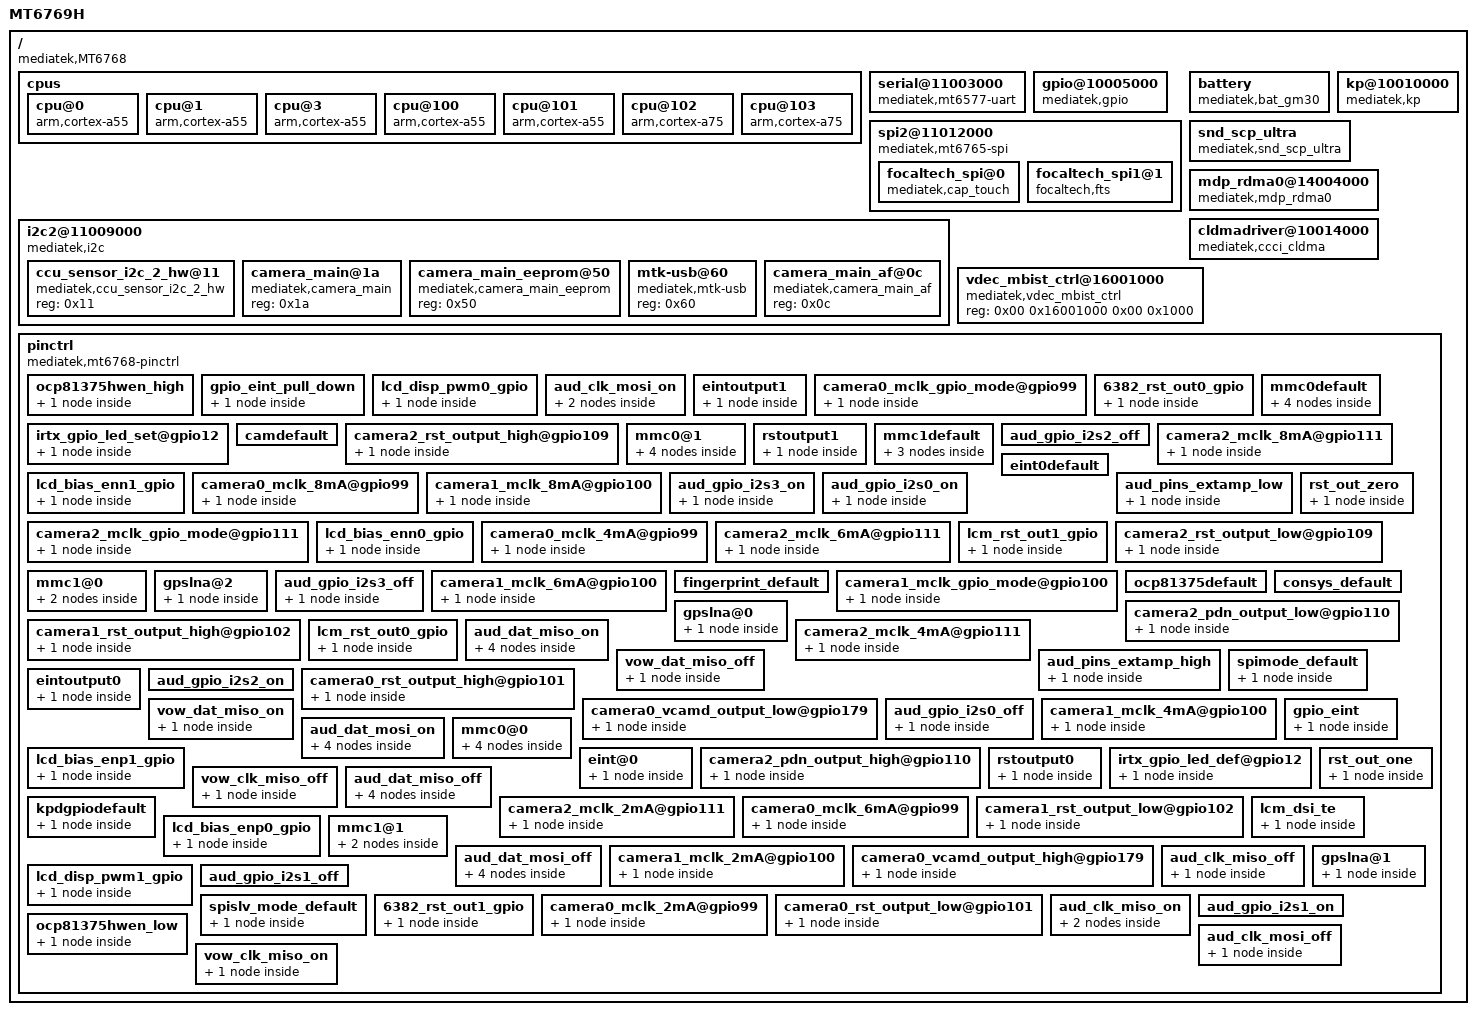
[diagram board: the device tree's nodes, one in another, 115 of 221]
/dts-v1/;

/ {
    model-part-name = "MT6769H";
	#address-cells = <0x02>;
	model = "MT6769H";
	#size-cells = <0x02>;
	interrupt-parent = <0x01>;
	compatible = "mediatek,MT6768";
	model-external-name = "MT6769H";

    cpus {
        #address-cells = <0x01>;
		#size-cells = <0x00>;
        cpu@0 {
            capacity-dmips-mhz = <0x1ef>;
			clock-frequency = <0x65633340>;
			cpu-idle-states = <0x03 0x04 0x05 0x06 0x07 0x08 0x09>;
			device_type = "cpu";
			compatible = "arm,cortex-a55";
			dynamic-power-coefficient = <0x55>;
			reg = <0x00>;
			enable-method = "psci";
			phandle = <0x0b>;
			operating-points-v2 = <0x02>;
        };
        cpu@1 {
            capacity-dmips-mhz = <0x1ef>;
			clock-frequency = <0x65633340>;
			cpu-idle-states = <0x03 0x04 0x05 0x06 0x07 0x08 0x09>;
			device_type = "cpu";
			compatible = "arm,cortex-a55";
			dynamic-power-coefficient = <0x55>;
			reg = <0x100>;
			enable-method = "psci";
			phandle = <0x0c>;
			operating-points-v2 = <0x02>;
        };
        cpu@3 {
			capacity-dmips-mhz = <0x1ef>;
			clock-frequency = <0x65633340>;
			cpu-idle-states = <0x03 0x04 0x05 0x06 0x07 0x08 0x09>;
			device_type = "cpu";
			compatible = "arm,cortex-a55";
			dynamic-power-coefficient = <0x55>;
			reg = <0x300>;
			enable-method = "psci";
			phandle = <0x0e>;
			operating-points-v2 = <0x02>;
		};
        cpu@100 {
			capacity-dmips-mhz = <0x1ef>;
			clock-frequency = <0x65633340>;
			cpu-idle-states = <0x03 0x04 0x05 0x06 0x07 0x08 0x09>;
			device_type = "cpu";
			compatible = "arm,cortex-a55";
			dynamic-power-coefficient = <0x55>;
			reg = <0x400>;
			enable-method = "psci";
			phandle = <0x0f>;
			operating-points-v2 = <0x02>;
		};
        cpu@101 {
			capacity-dmips-mhz = <0x1ef>;
			clock-frequency = <0x65633340>;
			cpu-idle-states = <0x03 0x04 0x05 0x06 0x07 0x08 0x09>;
			device_type = "cpu";
			compatible = "arm,cortex-a55";
			dynamic-power-coefficient = <0x55>;
			reg = <0x500>;
			enable-method = "psci";
			phandle = <0x10>;
			operating-points-v2 = <0x02>;
		};
        cpu@102 {
			capacity-dmips-mhz = <0x400>;
			clock-frequency = <0x8166d4c0>;
			cpu-idle-states = <0x03 0x04 0x05 0x06 0x07 0x08 0x09>;
			device_type = "cpu";
			compatible = "arm,cortex-a75";
			dynamic-power-coefficient = <0x113>;
			reg = <0x600>;
			enable-method = "psci";
			phandle = <0x11>;
			operating-points-v2 = <0x0a>;
		};
        cpu@103 {
			capacity-dmips-mhz = <0x400>;
			clock-frequency = <0x8166d4c0>;
			cpu-idle-states = <0x03 0x04 0x05 0x06 0x07 0x08 0x09>;
			device_type = "cpu";
			compatible = "arm,cortex-a75";
			dynamic-power-coefficient = <0x113>;
			reg = <0x700>;
			enable-method = "psci";
			phandle = <0x12>;
			operating-points-v2 = <0x0a>;
		};
    };

    serial@11003000 {
		clock-names = "baud\0bus";
		interrupts = <0x00 0x71 0x08>;
		clocks = <0x15 0x26 0x17>;
		dma-names = "tx\0rx";
		compatible = "mediatek,mt6577-uart";
		reg = <0x00 0x11003000 0x00 0x1000>;
		phandle = <0xc0>;
		dmas = <0x39 0x02 0x39 0x03>;
	};

    gpio@10005000 {
		gpio_init_default = <0x00 0x00 0x00 0x00 0x01 0x01 0x01 0x01 0x00 0x00 0x00 0x00 0x01 0x01 0x02 0x00 0x00 0x00 0x01 0x00 0x01 0x03 0x00 0x00 0x00 0x01 0x01 0x00 0x04 0x00 0x00 0x00 0x01 0x01 0x01 0x05 0x00 0x00 0x00 0x01 0x00 0x00 0x06 0x00 0x00 0x00 0x01 0x01 0x01 0x07 0x00 0x00 0x00 0x01 0x01 0x00 0x08 0x00 0x00 0x00 0x01 0x01 0x00 0x09 0x00 0x00 0x00 0x01 0x00 0x00 0x0a 0x00 0x00 0x00 0x01 0x01 0x00 0x0b 0x01 0x00 0x00 0x01 0x00 0x00 0x0c 0x02 0x00 0x00 0x01 0x00 0x00 0x0d 0x02 0x00 0x00 0x01 0x00 0x00 0x0e 0x02 0x01 0x00 0x00 0x00 0x00 0x0f 0x02 0x01 0x00 0x00 0x00 0x00 0x10 0x02 0x01 0x00 0x00 0x00 0x00 0x11 0x00 0x00 0x00 0x01 0x00 0x01 0x12 0x00 0x00 0x00 0x01 0x01 0x01 0x13 0x00 0x01 0x00 0x01 0x00 0x01 0x14 0x00 0x01 0x00 0x01 0x00 0x01 0x15 0x00 0x00 0x00 0x01 0x01 0x00 0x16 0x00 0x00 0x00 0x01 0x00 0x00 0x17 0x00 0x00 0x00 0x00 0x00 0x00 0x18 0x05 0x00 0x00 0x01 0x00 0x00 0x19 0x02 0x00 0x00 0x01 0x00 0x00 0x1a 0x02 0x00 0x00 0x00 0x00 0x00 0x1b 0x02 0x01 0x00 0x00 0x00 0x00 0x1c 0x02 0x00 0x00 0x00 0x00 0x00 0x1d 0x00 0x01 0x00 0x00 0x00 0x00 0x1e 0x00 0x01 0x00 0x00 0x00 0x00 0x1f 0x00 0x01 0x00 0x01 0x01 0x00 0x20 0x01 0x00 0x00 0x01 0x00 0x00 0x21 0x01 0x01 0x00 0x00 0x00 0x00 0x22 0x01 0x01 0x00 0x00 0x00 0x00 0x23 0x01 0x01 0x00 0x00 0x00 0x00 0x24 0x00 0x01 0x01 0x00 0x00 0x00 0x25 0x02 0x01 0x00 0x00 0x00 0x00 0x26 0x00 0x00 0x00 0x00 0x00 0x01 0x27 0x00 0x00 0x00 0x01 0x01 0x01 0x28 0x02 0x00 0x00 0x01 0x00 0x00 0x29 0x00 0x00 0x00 0x01 0x01 0x01 0x2a 0x00 0x01 0x00 0x01 0x01 0x01 0x2b 0x01 0x01 0x00 0x00 0x00 0x00 0x2c 0x01 0x00 0x00 0x01 0x00 0x00 0x2d 0x00 0x01 0x00 0x00 0x00 0x00 0x2e 0x01 0x00 0x00 0x01 0x01 0x00 0x2f 0x01 0x00 0x00 0x01 0x01 0x00 0x30 0x01 0x00 0x00 0x01 0x01 0x01 0x31 0x01 0x00 0x00 0x01 0x01 0x01 0x32 0x01 0x00 0x00 0x01 0x01 0x01 0x33 0x01 0x00 0x00 0x01 0x01 0x01 0x34 0x01 0x00 0x00 0x01 0x00 0x00 0x35 0x01 0x00 0x00 0x01 0x00 0x00 0x36 0x01 0x00 0x00 0x01 0x00 0x00 0x37 0x01 0x00 0x00 0x01 0x00 0x00 0x38 0x01 0x00 0x00 0x01 0x00 0x00 0x39 0x01 0x00 0x00 0x01 0x00 0x00 0x3a 0x00 0x00 0x00 0x01 0x00 0x00 0x3b 0x01 0x00 0x00 0x01 0x00 0x00 0x3c 0x01 0x00 0x00 0x01 0x00 0x00 0x3d 0x01 0x00 0x00 0x01 0x00 0x00 0x3e 0x01 0x00 0x00 0x01 0x00 0x00 0x3f 0x01 0x00 0x00 0x01 0x00 0x00 0x40 0x01 0x00 0x00 0x01 0x00 0x00 0x41 0x01 0x00 0x00 0x01 0x00 0x00 0x42 0x01 0x00 0x00 0x01 0x00 0x00 0x43 0x01 0x00 0x00 0x01 0x00 0x00 0x44 0x01 0x00 0x00 0x01 0x00 0x00 0x45 0x01 0x00 0x00 0x01 0x00 0x00 0x46 0x01 0x00 0x00 0x01 0x00 0x00 0x47 0x01 0x00 0x00 0x01 0x00 0x00 0x48 0x01 0x00 0x00 0x01 0x00 0x00 0x49 0x01 0x00 0x00 0x01 0x00 0x00 0x4a 0x01 0x00 0x00 0x01 0x00 0x00 0x4b 0x01 0x00 0x00 0x01 0x00 0x00 0x4c 0x01 0x00 0x00 0x01 0x00 0x00 0x4d 0x01 0x00 0x00 0x01 0x00 0x00 0x4e 0x01 0x00 0x00 0x01 0x00 0x00 0x4f 0x00 0x00 0x00 0x01 0x00 0x00 0x50 0x00 0x00 0x00 0x01 0x00 0x00 0x51 0x02 0x00 0x00 0x01 0x01 0x01 0x52 0x01 0x00 0x00 0x01 0x01 0x01 0x53 0x01 0x00 0x00 0x01 0x01 0x01 0x54 0x02 0x00 0x00 0x01 0x01 0x01 0x55 0x02 0x00 0x00 0x01 0x00 0x00 0x56 0x02 0x01 0x00 0x00 0x00 0x00 0x57 0x02 0x01 0x00 0x00 0x00 0x00 0x58 0x02 0x01 0x00 0x00 0x00 0x00 0x59 0x01 0x00 0x00 0x01 0x01 0x01 0x5a 0x01 0x00 0x00 0x01 0x01 0x01 0x5b 0x00 0x00 0x00 0x00 0x00 0x00 0x5c 0x01 0x01 0x00 0x00 0x00 0x00 0x5d 0x01 0x00 0x00 0x01 0x01 0x00 0x5e 0x00 0x01 0x00 0x00 0x00 0x00 0x5f 0x01 0x00 0x00 0x01 0x01 0x00 0x60 0x01 0x01 0x00 0x00 0x00 0x00 0x61 0x00 0x00 0x00 0x01 0x01 0x00 0x62 0x00 0x00 0x00 0x01 0x00 0x00 0x63 0x01 0x01 0x00 0x00 0x00 0x00 0x64 0x01 0x01 0x00 0x00 0x00 0x00 0x65 0x00 0x01 0x00 0x00 0x00 0x00 0x66 0x00 0x01 0x00 0x00 0x00 0x00 0x67 0x01 0x00 0x00 0x01 0x01 0x01 0x68 0x01 0x00 0x00 0x01 0x01 0x01 0x69 0x01 0x00 0x00 0x01 0x01 0x01 0x6a 0x01 0x00 0x00 0x01 0x01 0x01 0x6b 0x00 0x00 0x00 0x00 0x01 0x00 0x6c 0x00 0x00 0x00 0x00 0x00 0x00 0x6d 0x00 0x01 0x00 0x00 0x00 0x00 0x6e 0x00 0x01 0x00 0x00 0x00 0x00 0x6f 0x01 0x01 0x00 0x00 0x00 0x00 0x70 0x00 0x00 0x00 0x00 0x00 0x00 0x71 0x00 0x00 0x00 0x01 0x00 0x00 0x72 0x00 0x00 0x00 0x01 0x00 0x00 0x73 0x00 0x00 0x00 0x01 0x00 0x00 0x74 0x00 0x00 0x00 0x01 0x00 0x00 0x75 0x00 0x00 0x00 0x01 0x00 0x00 0x76 0x00 0x00 0x00 0x01 0x00 0x00 0x77 0x00 0x00 0x00 0x01 0x00 0x00 0x78 0x00 0x00 0x00 0x01 0x00 0x00 0x79 0x00 0x00 0x00 0x01 0x00 0x00 0x86 0x01 0x00 0x00 0x01 0x00 0x01 0x87 0x01 0x01 0x00 0x00 0x00 0x00 0x88 0x01 0x01 0x00 0x00 0x00 0x00 0x89 0x01 0x01 0x00 0x00 0x00 0x00 0x8a 0x01 0x01 0x00 0x00 0x00 0x00 0x8b 0x01 0x01 0x00 0x00 0x00 0x00 0x8c 0x01 0x00 0x00 0x01 0x00 0x00 0x8d 0x01 0x00 0x00 0x01 0x00 0x00 0x8e 0x01 0x00 0x00 0x01 0x00 0x00 0x8f 0x01 0x00 0x00 0x01 0x00 0x00 0x90 0x01 0x00 0x00 0x01 0x00 0x00 0x91 0x01 0x01 0x00 0x00 0x00 0x00 0x92 0x01 0x01 0x00 0x00 0x00 0x00 0x93 0x01 0x01 0x00 0x00 0x00 0x00 0x94 0x01 0x01 0x00 0x00 0x00 0x00 0x95 0x01 0x01 0x00 0x00 0x00 0x00 0x96 0x00 0x01 0x00 0x00 0x00 0x00 0x97 0x04 0x01 0x00 0x00 0x00 0x00 0x98 0x00 0x01 0x00 0x00 0x00 0x00 0x99 0x00 0x01 0x00 0x00 0x00 0x00 0x9a 0x01 0x01 0x00 0x00 0x00 0x00 0x9b 0x01 0x00 0x00 0x01 0x01 0x00 0x9c 0x01 0x01 0x00 0x00 0x00 0x00 0x9d 0x01 0x01 0x00 0x00 0x00 0x00 0x9e 0x00 0x01 0x00 0x00 0x00 0x00 0x9f 0x00 0x01 0x00 0x00 0x00 0x00 0xa0 0x00 0x01 0x00 0x01 0x01 0x00 0xa1 0x01 0x00 0x00 0x01 0x01 0x01 0xa2 0x01 0x00 0x00 0x01 0x01 0x01 0xa3 0x01 0x00 0x00 0x01 0x01 0x01 0xa4 0x01 0x00 0x00 0x01 0x01 0x01 0xa5 0x00 0x01 0x00 0x00 0x00 0x00 0xa6 0x00 0x01 0x00 0x00 0x00 0x00 0xa7 0x01 0x00 0x00 0x01 0x00 0x00 0xa8 0x01 0x00 0x00 0x01 0x00 0x00 0xa9 0x00 0x01 0x00 0x00 0x00 0x00 0xaa 0x01 0x00 0x00 0x01 0x01 0x01 0xab 0x01 0x01 0x00 0x00 0x00 0x01 0xac 0x01 0x01 0x00 0x00 0x00 0x00 0xad 0x01 0x01 0x00 0x00 0x00 0x00 0xae 0x01 0x00 0x00 0x01 0x01 0x00 0xaf 0x01 0x00 0x00 0x01 0x01 0x01 0xb0 0x01 0x00 0x00 0x01 0x01 0x01 0xb2 0x00 0x01 0x00 0x00 0x00 0x00 0xb3 0x00 0x01 0x00 0x00 0x00 0x00 0xb4 0x00 0x00 0x00 0x01 0x00 0x00 0xb5 0x00 0x00 0x00 0x01 0x00 0x00 0xb6 0x00 0x00 0x00 0x01 0x00 0x00 0xb7 0x00 0x00 0x00 0x01 0x00 0x00 0xb8 0x00 0x00 0x00 0x01 0x00 0x00 0xb9 0x00 0x00 0x00 0x01 0x00 0x00 0xba 0x00 0x00 0x00 0x01 0x00 0x00>;
		compatible = "mediatek,gpio\0syscon";
		reg = <0x00 0x10005000 0x00 0x1000>;
		phandle = <0x16>;
	};

    spi2@11012000 {
		#address-cells = <0x01>;
		clock-names = "parent-clk\0sel-clk\0spi-clk";
		interrupts = <0x00 0x91 0x08>;
		clocks = <0x14 0x0b 0x14 0x5b 0x26 0x37>;
		#size-cells = <0x00>;
		compatible = "mediatek,mt6765-spi";
		status = "okay";
		reg = <0x00 0x11012000 0x00 0x1000>;
		phandle = <0xd6>;
		mediatek,pad-select = <0x00>;

		focaltech_spi@0 {
			spi-max-frequency = <0x5b8d80>;
			compatible = "mediatek,cap_touch";
			reg = <0x00>;
		};

		focaltech_spi1@1 {
			spi-max-frequency = <0x5b8d80>;
			compatible = "focaltech,fts";
			reg = <0x00>;
		};
	};

    battery {
		g_FG_PSEUDO100_T0 = <0x5f>;
		SHUTDOWN_1_TIME = <0x78>;
		battery1_profile_t3_col = <0x03>;
		battery0_profile_t0 = <0x00 0xaba4 0x3f2 0x203 0xaaf3 0x3f2 0x405 0xaa6c 0x3f1 0x608 0xa9ee 0x3ea 0x80b 0xa970 0x3f0 0xa0e 0xa8ef 0x3eb 0xc10 0xa86a 0x3f2 0xe13 0xa7ec 0x3ee 0x1016 0xa76e 0x3e8 0x1219 0xa6ef 0x3ed 0x141b 0xa671 0x3f2 0x161e 0xa5f3 0x3f2 0x1821 0xa575 0x3f2 0x1a24 0xa4f7 0x3f2 0x1c26 0xa480 0x3f9 0x1e29 0xa405 0x3fc 0x202c 0xa38f 0x3fc 0x222f 0xa313 0x3f3 0x2431 0xa29e 0x3fb 0x2634 0xa22a 0x3fc 0x2837 0xa1ad 0x3fc 0x2a3a 0xa13a 0x3fd 0x2c3c 0xa0d0 0x406 0x2e3f 0xa05c 0x406 0x3042 0x9fe9 0x408 0x3245 0x9f78 0x410 0x3447 0x9f0f 0x413 0x364a 0x9ea2 0x41e 0x384d 0x9e37 0x424 0x3a50 0x9dd4 0x429 0x3c52 0x9d6a 0x42e 0x3e55 0x9d01 0x42e 0x4058 0x9c9f 0x43a 0x425b 0x9c40 0x442 0x445d 0x9bda 0x442 0x4660 0x9b81 0x44a 0x4863 0x9b24 0x465 0x4a66 0x9acf 0x461 0x4c68 0x9a71 0x469 0x4e6b 0x9a1c 0x487 0x506e 0x99c8 0x489 0x5271 0x9969 0x4a5 0x5473 0x98fd 0x491 0x5676 0x987e 0x47c 0x5879 0x97f7 0x439 0x5a7c 0x977f 0x415 0x5c7e 0x971c 0x403 0x5e81 0x96cc 0x3f8 0x6084 0x9687 0x3f2 0x6287 0x9643 0x3ed 0x6489 0x95fe 0x3e8 0x668c 0x95c5 0x3e8 0x688f 0x9591 0x3ee 0x6a92 0x955c 0x3f2 0x6c94 0x9528 0x3f2 0x6e97 0x94fb 0x3ea 0x709a 0x94d1 0x3f9 0x729d 0x949e 0x3f3 0x749f 0x9473 0x3fb 0x76a2 0x9453 0x406 0x78a5 0x9429 0x406 0x7aa8 0x940a 0x40f 0x7caa 0x93e9 0x407 0x7ead 0x93c1 0x410 0x80b0 0x93a4 0x412 0x82b3 0x938f 0x41d 0x84b5 0x9377 0x424 0x86b8 0x935b 0x424 0x88bb 0x9346 0x428 0x8abe 0x932c 0x429 0x8cc0 0x930d 0x424 0x8ec3 0x92dc 0x40d 0x90c6 0x92a3 0x3f0 0x92c9 0x926f 0x3ef 0x94cb 0x9248 0x3f2 0x96ce 0x9221 0x3fa 0x98d1 0x91ff 0x3fc 0x9ad4 0x91e0 0x3fc 0x9cd6 0x91b7 0x3fc 0x9ed9 0x9197 0x3fc 0xa0dc 0x9177 0x406 0xa2df 0x9157 0x411 0xa4e1 0x912b 0x419 0xa6e4 0x90ec 0x410 0xa8e7 0x90ad 0x40e 0xaaea 0x9070 0x40b 0xacec 0x9035 0x41d 0xaeef 0x8fe4 0x415 0xb0f2 0x8f9b 0x404 0xb2f5 0x8f7b 0x423 0xb4f7 0x8f60 0x448 0xb6fa 0x8f35 0x462 0xb8fd 0x8ed5 0x477 0xbb00 0x8e13 0x477 0xbd02 0x8cd5 0x47b 0xbf05 0x8b03 0x46e 0xc108 0x88a7 0x472 0xc30b 0x85d9 0x47d 0xc50d 0x825c 0x4a3 0xc710 0x821e 0x4a6>;
		TEMPERATURE_T4 = <0xfffffff6>;
		CAR_TUNE_VALUE = <0x64>;
		battery0_profile_t1_num = <0x64>;
		battery0_profile_t5_num = <0x64>;
		TEMPERATURE_T2 = <0x0a>;
		battery1_profile_t2_num = <0x64>;
		battery0_profile_t3_col = <0x03>;
		TEMPERATURE_T0 = <0x32>;
		DIFFERENCE_FULLOCV_ITH = <0xc8>;
		battery1_profile_t0_col = <0x03>;
		battery1_profile_t4 = <0x00 0xab8a 0x1c20 0x1f4 0xaa9e 0x1c20 0x3e8 0xa9e1 0x1be9 0x5dc 0xa930 0x1b85 0x7d0 0xa892 0x1b17 0x9c4 0xa7fa 0x1ab3 0xbb8 0xa769 0x1a59 0xdac 0xa6dd 0x19fa 0xfa0 0xa652 0x198f 0x1194 0xa5cc 0x193e 0x1388 0xa550 0x18f9 0x157c 0xa4ce 0x18a4 0x1770 0xa452 0x1860 0x1964 0xa3dc 0x1831 0x1b58 0xa363 0x17fa 0x1d4c 0xa2f1 0x17cd 0x1f40 0xa27b 0x1796 0x2134 0xa20b 0x177d 0x2328 0xa19c 0x1761 0x251c 0xa126 0x1740 0x2710 0xa0b6 0x1741 0x2904 0xa047 0x171b 0x2af8 0x9fdd 0x170a 0x2cec 0x9f7d 0x1711 0x2ee0 0x9f20 0x1719 0x30d4 0x9eb7 0x1702 0x32c8 0x9e41 0x16dd 0x34bc 0x9dbc 0x16a6 0x36b0 0x9d30 0x1660 0x38a4 0x9ca5 0x163a 0x3a98 0x9c22 0x1629 0x3c8c 0x9ba6 0x1621 0x3e80 0x9b3a 0x162b 0x4074 0x9ad7 0x1633 0x4268 0x9a7a 0x1649 0x445c 0x9a23 0x1651 0x4650 0x99cc 0x1630 0x4844 0x9972 0x1619 0x4a38 0x9918 0x1612 0x4c2c 0x98bb 0x15f2 0x4e20 0x985b 0x15cc 0x5014 0x97fb 0x159f 0x5208 0x979e 0x1586 0x53fc 0x9744 0x1568 0x55f0 0x96ea 0x1548 0x57e4 0x9696 0x1531 0x59d8 0x9649 0x1513 0x5bcc 0x95fb 0x14fa 0x5dc0 0x95b7 0x1511 0x5fb4 0x9573 0x150c 0x61a8 0x9535 0x150c 0x639c 0x94fa 0x151b 0x6590 0x94c9 0x153b 0x6784 0x9494 0x1543 0x6978 0x9468 0x155e 0x6b6c 0x943a 0x1570 0x6d60 0x9415 0x1590 0x6f54 0x93f0 0x15b5 0x7148 0x93d1 0x15ed 0x733c 0x93ae 0x1621 0x7530 0x9393 0x1642 0x7724 0x9377 0x1679 0x7918 0x935b 0x16a6 0x7b0c 0x933f 0x16d5 0x7d00 0x9320 0x1702 0x7ef4 0x9304 0x172a 0x80e8 0x92e5 0x1757 0x82dc 0x92c3 0x178e 0x84d0 0x92a4 0x17b6 0x86c4 0x9282 0x17db 0x88b8 0x925c 0x1801 0x8aac 0x9231 0x1822 0x8ca0 0x920c 0x1838 0x8e94 0x91e0 0x184f 0x9088 0x91b2 0x1877 0x927c 0x917a 0x189c 0x9470 0x9142 0x18c4 0x9664 0x9107 0x18e2 0x9858 0x90c3 0x1919 0x9a4c 0x9079 0x193a 0x9c40 0x902b 0x1967 0x9e34 0x8fd8 0x1987 0xa028 0x8f7e 0x199e 0xa21c 0x8f1e 0x19c6 0xa410 0x8eba 0x19f0 0xa604 0x8e51 0x1a20 0xa7f8 0x8dde 0x1a57 0xa9ec 0x8d6c 0x1aae 0xabe0 0x8cf3 0x1b03 0xadd4 0x8c7a 0x1b76 0xafc8 0x8c01 0x1c0a 0xb1bc 0x8b8e 0x1cb4 0xb3b0 0x8b1f 0x1dae 0xb5a4 0x8ab8 0x1ef8 0xb798 0x8a52 0x20d3 0xb98c 0x89e2 0x237b 0xbb80 0x895d 0x2783 0xbd74 0x889a 0x2d1e 0xbf68 0x8748 0x3451 0xc15c 0x8523 0x3e3f>;
		battery1_profile_t4_col = <0x03>;
		battery_id_gpio = <0x20 0x17 0x00>;
		battery0_profile_t5 = <0x00 0xab36 0x4ca4 0x203 0xa960 0x4cab 0x405 0xa7c0 0x4d2a 0x608 0xa650 0x4d05 0x80b 0xa529 0x4b03 0xa0e 0xa42b 0x48de 0xc10 0xa33f 0x4712 0xe13 0xa269 0x45ef 0x1016 0xa1ad 0x44e1 0x1219 0xa100 0x4406 0x141b 0xa049 0x4302 0x161e 0x9f86 0x41d7 0x1821 0x9ebf 0x40db 0x1a24 0x9dfd 0x3f7d 0x1c26 0x9d4a 0x3e5d 0x1e29 0x9cae 0x3da9 0x202c 0x9c22 0x3cad 0x222f 0x9b89 0x3ba2 0x2431 0x9b20 0x3b37 0x2634 0x9ab8 0x3b09 0x2837 0x9a4f 0x3ac2 0x2a3a 0x99dc 0x3a64 0x2c3c 0x997d 0x3a02 0x2e3f 0x9915 0x39fc 0x3042 0x98b7 0x39bb 0x3245 0x984c 0x3984 0x3447 0x97e0 0x3a2c 0x364a 0x978c 0x38bf 0x384d 0x9738 0x37f5 0x3a50 0x96e4 0x3856 0x3c52 0x9694 0x3874 0x3e55 0x964b 0x3877 0x4058 0x95fc 0x3895 0x425b 0x95bb 0x38f2 0x445d 0x9580 0x38ea 0x4660 0x9541 0x38c2 0x4863 0x9502 0x38f6 0x4a66 0x94c3 0x395f 0x4c68 0x9484 0x394c 0x4e6b 0x9456 0x3842 0x506e 0x9423 0x385a 0x5271 0x93ef 0x39f4 0x5473 0x93b1 0x3a3f 0x5676 0x937c 0x3a87 0x5879 0x933f 0x3abe 0x5a7c 0x9312 0x3b0a 0x5c7e 0x92d5 0x3b59 0x5e81 0x929e 0x3b93 0x6084 0x9262 0x3bc7 0x6287 0x922d 0x3c14 0x6489 0x91f9 0x3c68 0x668c 0x91c5 0x3cb2 0x688f 0x918c 0x3cf0 0x6a92 0x9152 0x3d45 0x6c94 0x911e 0x3d9c 0x6e97 0x90e9 0x3e00 0x709a 0x90b5 0x3e50 0x729d 0x9080 0x3eae 0x749f 0x904c 0x3f2f 0x76a2 0x9017 0x3f73 0x78a5 0x8fe3 0x4014 0x7aa8 0x8faf 0x4024 0x7caa 0x8f84 0x40ae 0x7ead 0x8f46 0x410f 0x80b0 0x8f1c 0x418e 0x82b3 0x8ee8 0x4219 0x84b5 0x8ebc 0x42af 0x86b8 0x8e88 0x432c 0x88bb 0x8e53 0x43c4 0x8abe 0x8e22 0x4457 0x8cc0 0x8df5 0x44f2 0x8ec3 0x8dc1 0x458a 0x90c6 0x8d8c 0x480c 0x92c9 0x8d58 0x486e 0x94cb 0x8d23 0x4746 0x96ce 0x8cfb 0x48a9 0x98d1 0x8cc1 0x49ae 0x9ad4 0x8c86 0x4a79 0x9cd6 0x8c49 0x4b15 0x9ed9 0x8c0a 0x4c22 0xa0dc 0x8bcc 0x4d56 0xa2df 0x8b8e 0x4e3f 0xa4e1 0x8b45 0x4f55 0xa6e4 0x8b05 0x50d4 0xa8e7 0x8ab1 0x5200 0xaaea 0x8a5d 0x538c 0xacec 0x8a06 0x5517 0xaeef 0x899d 0x574c 0xb0f2 0x892f 0x59da 0xb2f5 0x88ae 0x5c82 0xb4f7 0x882b 0x5eed 0xb6fa 0x87c2 0x5f4a 0xb8fd 0x874b 0x5e19 0xbb00 0x86ac 0x5cba 0xbd02 0x85dd 0x5a97 0xbf05 0x84c6 0x582a 0xc108 0x84c6 0x582a 0xc30b 0x84c6 0x582a 0xc50d 0x84c6 0x582a 0xc710 0x84c6 0x582a>;
		battery0_profile_t2_num = <0x64>;
		PMIC_SHUTDOWN_CURRENT = <0x14>;
		battery1_profile_t2 = <0x00 0xab11 0xad7 0x1f4 0xaa5a 0xad7 0x3e8 0xa9bf 0xac8 0x5dc 0xa92a 0xa78 0x7d0 0xa898 0xa44 0x9c4 0xa810 0xa14 0xbb8 0xa785 0x9d1 0xdac 0xa702 0x9a1 0xfa0 0xa683 0x96a 0x1194 0xa604 0x944 0x1388 0xa585 0x915 0x157c 0xa50c 0x906 0x1770 0xa490 0x8c8 0x1964 0xa417 0x8b1 0x1b58 0xa3a4 0x8a7 0x1d4c 0xa32f 0x88c 0x1f40 0xa2bf 0x882 0x2134 0xa249 0x861 0x2328 0xa1da 0x86b 0x251c 0xa164 0x855 0x2710 0xa0f1 0x84b 0x2905 0xa082 0x846 0x2afa 0xa00f 0x846 0x2cef 0x9fa5 0x843 0x2ee4 0x9f45 0x861 0x30d9 0x9efb 0x889 0x32cd 0x9e9e 0x882 0x34c1 0x9e25 0x855 0x36b5 0x9d87 0x81e 0x38aa 0x9cec 0x816 0x3a9e 0x9c67 0x837 0x3c93 0x9bf4 0x84d 0x3e88 0x9b97 0x873 0x407d 0x9b49 0x891 0x4272 0x9b08 0x8cf 0x4466 0x9acd 0x8ed 0x465a 0x9a89 0x8f7 0x484e 0x9a3c 0x8f7 0x4a42 0x99e5 0x8f0 0x4c36 0x998b 0x8f0 0x4e2a 0x9928 0x8cf 0x501e 0x98c1 0x8af 0x5212 0x9852 0x873 0x5406 0x97e5 0x83c 0x55fa 0x977f 0x81e 0x57ee 0x971f 0x7ee 0x59e2 0x96c5 0x7d7 0x5bd6 0x9677 0x7c6 0x5dca 0x9630 0x7b0 0x5fbe 0x95ef 0x7b7 0x61b2 0x95b4 0x7b0 0x63a6 0x957f 0x7b7 0x659a 0x954e 0x7ba 0x678e 0x951c 0x7be 0x6982 0x94f1 0x7c1 0x6b76 0x94c9 0x7c9 0x6d6a 0x94a3 0x7d7 0x6f5e 0x947b 0x7df 0x7152 0x9459 0x7e6 0x7347 0x943a 0x7ee 0x753c 0x941e 0x7fd 0x7731 0x9405 0x80c 0x7926 0x93ec 0x814 0x7b1b 0x93da 0x82d 0x7d10 0x93ca 0x84b 0x7f05 0x93c1 0x864 0x80fa 0x93b2 0x873 0x82ef 0x93a8 0x889 0x84e4 0x93a2 0x8aa 0x86d9 0x9396 0x8b8 0x88ce 0x938c 0x8d7 0x8ac3 0x9380 0x8f0 0x8cb8 0x9370 0x90e 0x8ead 0x935e 0x91c 0x90a2 0x9348 0x92c 0x9297 0x9329 0x93b 0x948b 0x9307 0x945 0x967f 0x92dc 0x94c 0x9873 0x92b0 0x963 0x9a67 0x9282 0x97c 0x9c5b 0x9253 0x99a 0x9e50 0x921b 0x9b0 0xa044 0x91e0 0x9ce 0xa238 0x9199 0x9ef 0xa42c 0x9142 0xa0d 0xa621 0x90e8 0xa2b 0xa815 0x9085 0xa5a 0xaa09 0x9019 0xa82 0xabfe 0x8f90 0xa89 0xadf3 0x8eff 0xa99 0xafe7 0x8e67 0xa91 0xb1db 0x8db3 0xa6c 0xb3cf 0x8ce6 0xa2b 0xb5c3 0x8c10 0xa2b 0xb7b7 0x8b37 0xa4b 0xb9ab 0x8a52 0xaaf 0xbb9f 0x88f7 0xb16 0xbd93 0x86b0 0xba9 0xbf88 0x83bb 0xd69 0xc17d 0x7fcf 0x1205>;
		g_FG_PSEUDO100_T3 = <0x5f>;
		Q_MAX_SYS_VOLTAGE_BAT2 = <0xd16>;
		battery0_profile_t3 = <0x00 0xab40 0xd20 0x203 0xaa82 0xd5b 0x405 0xa9bd 0x11ac 0x608 0xa90c 0x11cb 0x80b 0xa868 0x11ac 0xa0e 0xa7d2 0x1187 0xc10 0xa73b 0x1159 0xe13 0xa6b2 0x1139 0x1016 0xa629 0x110e 0x1219 0xa5a5 0x10d8 0x141b 0xa522 0x10b3 0x161e 0xa49f 0x1099 0x1821 0xa421 0x108a 0x1a24 0xa3aa 0x1072 0x1c26 0xa32f 0x1061 0x1e29 0xa2b9 0x105e 0x202c 0xa23d 0x1046 0x222f 0xa1c8 0x1040 0x2431 0xa154 0x1037 0x2634 0xa0d7 0x102c 0x2837 0xa063 0x1022 0x2a3a 0x9ff0 0x100f 0x2c3c 0x9f88 0x101b 0x2e3f 0x9f29 0x103b 0x3042 0x9ec7 0x1056 0x3245 0x9e50 0x105e 0x3447 0x9dcf 0x1058 0x364a 0x9d3c 0x1031 0x384d 0x9c98 0xfe3 0x3a50 0x9bfa 0xf98 0x3c52 0x9b67 0xf5e 0x3e55 0x9ade 0xf35 0x4058 0x9a62 0xf1c 0x425b 0x99fc 0xf21 0x445d 0x99a5 0xf2f 0x4660 0x9951 0xf3a 0x4863 0x98fd 0xf3c 0x4a66 0x98a0 0xf2b 0x4c68 0x984a 0xf28 0x4e6b 0x97ed 0xf01 0x506e 0x9798 0xeec 0x5271 0x9744 0xee2 0x5473 0x96f0 0xee2 0x5676 0x969e 0xee0 0x5879 0x9654 0xed8 0x5a7c 0x960b 0xed8 0x5c7e 0x95c1 0xedb 0x5e81 0x957c 0xee6 0x6084 0x953d 0xef0 0x6287 0x94fe 0xef1 0x6489 0x94be 0xef1 0x668c 0x9485 0xefc 0x688f 0x9451 0xf06 0x6a92 0x9423 0xf0a 0x6c94 0x93f9 0xf19 0x6e97 0x93cf 0xf1e 0x709a 0x93a5 0xf2f 0x729d 0x938c 0xf55 0x749f 0x936e 0xf92 0x76a2 0x934f 0xfb3 0x78a5 0x9339 0xfde 0x7aa8 0x931a 0x101c 0x7caa 0x9305 0x1051 0x7ead 0x92ef 0x1087 0x80b0 0x92d1 0x10c6 0x82b3 0x92b7 0x1102 0x84b5 0x9290 0x1137 0x86b8 0x9270 0x1173 0x88bb 0x9251 0x11b4 0x8abe 0x922d 0x11e8 0x8cc0 0x9203 0x1212 0x8ec3 0x91d9 0x123d 0x90c6 0x91af 0x127f 0x92c9 0x917e 0x12c1 0x94cb 0x9149 0x1300 0x96ce 0x910d 0x133f 0x98d1 0x90ce 0x136e 0x9ad4 0x908f 0x13a0 0x9cd6 0x903d 0x13d5 0x9ed9 0x8ff3 0x1413 0xa0dc 0x8f9e 0x143e 0xa2df 0x8f40 0x147d 0xa4e1 0x8ede 0x14b0 0xa6e4 0x8e6d 0x14da 0xa8e7 0x8dff 0x1501 0xaaea 0x8d84 0x1521 0xacec 0x8d0d 0x154b 0xaeef 0x8c93 0x158e 0xb0f2 0x8c1f 0x15e9 0xb2f5 0x8bad 0x165b 0xb4f7 0x8b3a 0x16ce 0xb6fa 0x8ac7 0x175e 0xb8fd 0x8a4d 0x181f 0xbb00 0x89c1 0x191a 0xbd02 0x8903 0x1a5e 0xbf05 0x87f2 0x1c06 0xc108 0x8669 0x1e4f 0xc30b 0x8438 0x21f7 0xc50d 0x83f4 0x226a 0xc710 0x83f4 0x226a>;
		FG_METER_RESISTANCE = <0x64>;
		battery1_profile_t3_num = <0x64>;
		battery0_profile_t0_col = <0x03>;
		battery1_profile_t0 = <0x00 0xaac6 0x354 0x1f4 0xaa2f 0x354 0x3e9 0xa9a0 0x363 0x5de 0xa90e 0x355 0x7d3 0xa880 0x355 0x9c8 0xa7f4 0x34d 0xbbd 0xa769 0x34d 0xdb2 0xa6e3 0x34d 0xfa7 0xa65e 0x34d 0x119c 0xa5df 0x355 0x1391 0xa560 0x355 0x1586 0xa4e4 0x354 0x177b 0xa465 0x346 0x1970 0xa3ef 0x354 0x1b65 0xa376 0x355 0x1d5a 0xa2fd 0x34d 0x1f4f 0xa281 0x34d 0x2143 0xa20e 0x355 0x2337 0xa199 0x35f 0x252b 0xa126 0x354 0x271f 0xa0b6 0x363 0x2913 0xa044 0x35f 0x2b07 0x9fd4 0x363 0x2cfc 0x9f64 0x35c 0x2ef1 0x9efb 0x36b 0x30e6 0x9e8e 0x36b 0x32db 0x9e25 0x373 0x34d0 0x9dbf 0x375 0x36c5 0x9d58 0x373 0x38ba 0x9cf5 0x37a 0x3aaf 0x9c92 0x37c 0x3ca4 0x9c35 0x38c 0x3e99 0x9bde 0x39a 0x408d 0x9b84 0x39a 0x4282 0x9b2a 0x39a 0x4476 0x9ad4 0x3a2 0x466b 0x9a83 0x3b1 0x4860 0x9a2f 0x3c0 0x4a55 0x99d8 0x3b8 0x4c4a 0x998b 0x3d9 0x4e3f 0x9937 0x3f0 0x5034 0x98d7 0x3e8 0x5229 0x986b 0x3e1 0x541e 0x97f5 0x3bb 0x5612 0x977f 0x38c 0x5807 0x971c 0x384 0x59fb 0x96bf 0x363 0x5bf0 0x966e 0x35c 0x5de5 0x962a 0x363 0x5fda 0x95ec 0x35c 0x61cf 0x95ae 0x34d 0x63c4 0x957c 0x35c 0x65b8 0x954b 0x364 0x67ac 0x951c 0x363 0x69a0 0x94eb 0x355 0x6b94 0x94bf 0x35c 0x6d88 0x9494 0x354 0x6f7c 0x946f 0x366 0x7171 0x9446 0x364 0x7366 0x9421 0x36b 0x755a 0x93ff 0x36b 0x774e 0x93e0 0x372 0x7942 0x93c4 0x373 0x7b36 0x93ab 0x37a 0x7d2a 0x9393 0x384 0x7f1e 0x9380 0x393 0x8112 0x936a 0x39b 0x8306 0x935b 0x3a2 0x84fa 0x934b 0x3b1 0x86ee 0x9339 0x3b4 0x88e2 0x931d 0x3aa 0x8ad7 0x92e8 0x37d 0x8ccb 0x92a4 0x35c 0x8ec0 0x9272 0x36b 0x90b5 0x9250 0x372 0x92aa 0x9234 0x382 0x949f 0x920f 0x372 0x9694 0x91e7 0x375 0x9889 0x91c5 0x375 0x9a7e 0x91a6 0x37c 0x9c73 0x9187 0x38c 0x9e68 0x9164 0x391 0xa05d 0x913c 0x39b 0xa252 0x90fe 0x393 0xa447 0x90ba 0x38c 0xa63c 0x9082 0x3a2 0xa831 0x9044 0x3aa 0xaa25 0x8fea 0x39a 0xac19 0x8fa0 0x3a2 0xae0e 0x8f7e 0x3ca 0xb003 0x8f46 0x3e1 0xb1f8 0x8eca 0x3e8 0xb3ed 0x8de1 0x3e8 0xb5e2 0x8cbe 0x3ff 0xb7d7 0x8b91 0x406 0xb9cc 0x8a20 0x3f7 0xbbc1 0x8802 0x3ff 0xbdb6 0x8564 0x415 0xbfab 0x821c 0x445 0xc1a0 0x7d85 0x4a9>;
		PMIC_MIN_VOL = <0x82dc>;
		g_FG_PSEUDO100_T1 = <0x5f>;
		Q_MAX_SYS_VOLTAGE_BAT0 = <0xd16>;
		battery0_profile_t4_col = <0x03>;
		battery0_profile_t1 = <0x00 0xabae 0x4f6 0x203 0xaaf4 0x4f8 0x405 0xaa76 0x517 0x608 0xa9f9 0x532 0x80b 0xa982 0x52c 0xa0e 0xa8f7 0x514 0xc10 0xa867 0x502 0xe13 0xa7e5 0x4e3 0x1016 0xa772 0x502 0x1219 0xa6f0 0x4f9 0x141b 0xa66c 0x4f6 0x161e 0xa5f9 0x514 0x1821 0xa573 0x4f0 0x1a24 0xa4f4 0x4ff 0x1c26 0xa480 0x514 0x1e29 0xa3f6 0x4e7 0x202c 0xa383 0x4f0 0x222f 0xa309 0x4f6 0x2431 0xa29d 0x511 0x2634 0xa22a 0x514 0x2837 0xa199 0x4d9 0x2a3a 0xa130 0x514 0x2c3c 0xa0c5 0x511 0x2e3f 0xa048 0x4fb 0x3042 0x9fd7 0x51a 0x3245 0x9f68 0x52a 0x3447 0x9efa 0x530 0x364a 0x9eb4 0x57d 0x384d 0x9e69 0x596 0x3a50 0x9dee 0x57a 0x3c52 0x9d51 0x55a 0x3e55 0x9cb3 0x543 0x4058 0x9c2e 0x55d 0x425b 0x9bd5 0x5a0 0x445d 0x9b93 0x5ca 0x4660 0x9b45 0x5a4 0x4863 0x9af9 0x5af 0x4a66 0x9a9e 0x59a 0x4c68 0x9a3f 0x5b2 0x4e6b 0x99d7 0x5d1 0x506e 0x9964 0x595 0x5271 0x98fa 0x56a 0x5473 0x9887 0x52e 0x5676 0x9815 0x50f 0x5879 0x97ac 0x4ef 0x5a7c 0x9748 0x4d0 0x5c7e 0x96f4 0x4c4 0x5e81 0x96a8 0x4cd 0x6084 0x9660 0x4ba 0x6287 0x9616 0x4ac 0x6489 0x95d6 0x49c 0x668c 0x95a3 0x4ad 0x688f 0x9573 0x4cd 0x6a92 0x953e 0x4c4 0x6c94 0x9502 0x4a4 0x6e97 0x94e2 0x4b3 0x709a 0x94b5 0x4ba 0x729d 0x9489 0x4ba 0x749f 0x945f 0x4d6 0x76a2 0x943f 0x4f5 0x78a5 0x941e 0x4f5 0x7aa8 0x93ed 0x4da 0x7caa 0x93dd 0x4ee 0x7ead 0x93ae 0x4bf 0x80b0 0x9397 0x4d8 0x82b3 0x937a 0x4d8 0x84b5 0x9365 0x4e2 0x86b8 0x9350 0x4ea 0x88bb 0x9340 0x4e5 0x8abe 0x9330 0x4e7 0x8cc0 0x931b 0x4f8 0x8ec3 0x930c 0x514 0x90c6 0x92f5 0x514 0x92c9 0x92cf 0x4eb 0x94cb 0x92bb 0x504 0x96ce 0x9298 0x4fc 0x98d1 0x9277 0x4f6 0x9ad4 0x9246 0x4db 0x9cd6 0x9224 0x510 0x9ed9 0x9204 0x514 0xa0dc 0x91da 0x515 0xa2df 0x91b0 0x536 0xa4e1 0x9184 0x55a 0xa6e4 0x9143 0x558 0xa8e7 0x90f7 0x552 0xaaea 0x90a8 0x560 0xacec 0x9066 0x586 0xaeef 0x900d 0x59c 0xb0f2 0x8fa6 0x593 0xb2f5 0x8f61 0x5c3 0xb4f7 0x8f27 0x5e2 0xb6fa 0x8eca 0x614 0xb8fd 0x8e3d 0x62c 0xbb00 0x8d6f 0x62c 0xbd02 0x8c4c 0x616 0xbf05 0x8ac9 0x5f6 0xc108 0x888e 0x5a4 0xc30b 0x85ca 0x5cc 0xc50d 0x824a 0x60b 0xc710 0x821e 0x60e>;
		MULTI_TEMP_GAUGE0 = <0x01>;
		TEMPERATURE_T5 = <0xffffffec>;
		battery1_profile_t1_col = <0x03>;
		enable_tmp_intr_suspend = <0x00>;
		battery1_profile_t5_col = <0x03>;
		compatible = "mediatek,bat_gm30";
		TEMPERATURE_T3 = <0x00>;
		battery0_profile_t3_num = <0x64>;
		COM_R_FG_VALUE = <0x00>;
		battery1_profile_t0_num = <0x64>;
		POWERON_SYSTEM_IBOOT = <0x1f4>;
		battery1_profile_t4_num = <0x64>;
		R_FG_VALUE = <0x05>;
		TEMPERATURE_T1 = <0x19>;
		battery0_profile_t1_col = <0x03>;
		battery1_profile_t5 = <0x00 0xab90 0x57da 0x204 0xaa3c 0x57c8 0x408 0xa8fd 0x5569 0x60c 0xa7d6 0x51ff 0x811 0xa6d6 0x4ec7 0xa15 0xa5ee 0x4bf2 0xc19 0xa527 0x4988 0xe1d 0xa46d 0x4751 0x1021 0xa3b8 0x456f 0x1225 0xa318 0x4477 0x142a 0xa288 0x42fb 0x162e 0xa1fe 0x41ad 0x1832 0xa186 0x4085 0x1a36 0xa118 0x3f18 0x1c3a 0xa0ac 0x3d8e 0x1e3e 0xa03c 0x3c9f 0x2043 0x9fcc 0x3bbb 0x2247 0x9f5f 0x3ac3 0x244b 0x9eed 0x39d5 0x264f 0x9e77 0x38f9 0x2853 0x9dff 0x3837 0x2a57 0x9d83 0x379d 0x2c5c 0x9d0e 0x3717 0x2e60 0x9c9d 0x3682 0x3064 0x9c2b 0x361b 0x3268 0x9bb2 0x3634 0x346c 0x9b46 0x3632 0x3670 0x9ad8 0x363e 0x3875 0x9a6f 0x3631 0x3a79 0x9a11 0x35f9 0x3c7d 0x99b4 0x35bb 0x3e81 0x994e 0x3590 0x4085 0x98f0 0x352d 0x4289 0x9893 0x3502 0x448d 0x982c 0x34e4 0x4692 0x97d0 0x34d9 0x4896 0x9773 0x34cb 0x4a9a 0x9718 0x349d 0x4c9e 0x96bc 0x349a 0x4ea2 0x966b 0x34b8 0x50a6 0x9621 0x34aa 0x52ab 0x95d1 0x34b7 0x54af 0x9589 0x34cc 0x56b3 0x9543 0x34ed 0x58b7 0x9502 0x3524 0x5abb 0x94c1 0x353e 0x5cbf 0x948a 0x357e 0x5ec4 0x9451 0x35e6 0x60c8 0x9419 0x3600 0x62cc 0x93e0 0x361f 0x64d0 0x93b1 0x3643 0x66d4 0x9383 0x3666 0x68d8 0x9355 0x3668 0x6add 0x932b 0x3685 0x6ce1 0x92fc 0x36c3 0x6ee5 0x92cf 0x36f3 0x70e9 0x92a6 0x3754 0x72ed 0x9276 0x3786 0x74f1 0x924a 0x37d7 0x76f6 0x9221 0x383f 0x78fa 0x91ef 0x38c7 0x7afe 0x91c4 0x393e 0x7d02 0x919b 0x3969 0x7f06 0x9171 0x399a 0x810a 0x9148 0x39d7 0x830f 0x9115 0x3ac5 0x8513 0x90ec 0x3ae8 0x8717 0x90c3 0x3b45 0x891b 0x9090 0x3bbf 0x8b1f 0x906f 0x3c18 0x8d23 0x903d 0x3c49 0x8f27 0x9014 0x3cad 0x912c 0x8fe9 0x3cd6 0x9330 0x8fb7 0x3d6a 0x9534 0x8f8b 0x3e3d 0x9738 0x8f58 0x3f00 0x993c 0x8f25 0x3f3a 0x9b40 0x8eee 0x3fa5 0x9d45 0x8eb4 0x402e 0x9f49 0x8e84 0x40f1 0xa14d 0x8e52 0x4181 0xa351 0x8e15 0x427f 0xa555 0x8ddb 0x437e 0xa759 0x8da3 0x442d 0xa95e 0x8d65 0x4554 0xab62 0x8d27 0x4697 0xad66 0x8ce9 0x47fe 0xaf6a 0x8ca4 0x499c 0xb16e 0x8c5c 0x4bc6 0xb372 0x8c0d 0x4ebc 0xb577 0x8bad 0x527a 0xb77b 0x8b37 0x57cc 0xb97f 0x8a9b 0x60ad 0xbb83 0x8a7a 0x62a2 0xbd87 0x8a7a 0x62a2 0xbf8b 0x8a7a 0x62a2 0xc190 0x8a7a 0x62a2 0xc394 0x8a7a 0x62a2 0xc598 0x8a7a 0x62a2 0xc79c 0x8a7a 0x62a2>;
		COM_FG_METER_RESISTANCE = <0x00>;
		phandle = <0xbc>;
		battery0_profile_t5_col = <0x03>;
		battery1_profile_t2_col = <0x03>;
		ACTIVE_TABLE = <0x06>;
		battery1_profile_t3 = <0x00 0xabb2 0x1432 0x1f4 0xaadc 0x1432 0x3e8 0xaa35 0x1423 0x5dc 0xa9a3 0x13f4 0x7d0 0xa90e 0x1397 0x9c4 0xa880 0x133b 0xbb8 0xa7f4 0x1304 0xdad 0xa769 0x12c5 0xfa2 0xa6e6 0x1287 0x1197 0xa664 0x122a 0x138c 0xa5e8 0x11dc 0x1581 0xa56c 0x11ad 0x1776 0xa4f3 0x116f 0x196b 0xa477 0x112b 0x1b5f 0xa405 0x110d 0x1d53 0xa38f 0x10d6 0x1f47 0xa31f 0x10cc 0x213b 0xa2b0 0x10b8 0x232f 0xa23a 0x109f 0x2523 0xa1ca 0x1089 0x2717 0xa157 0x1077 0x290b 0xa0e8 0x1059 0x2aff 0xa078 0x102a 0x2cf4 0xa00f 0x1025 0x2ee9 0x9fac 0x1016 0x30de 0x9f55 0x1025 0x32d2 0x9efe 0x1022 0x34c7 0x9e98 0x100c 0x36bc 0x9e1f 0xfee 0x38b1 0x9d8d 0xfa0 0x3aa6 0x9cf8 0xf71 0x3c9b 0x9c67 0xf3c 0x3e90 0x9beb 0xf44 0x4085 0x9b7b 0xf44 0x427a 0x9b21 0xf69 0x446e 0x9acd 0xf80 0x4662 0x9a83 0xfa8 0x4856 0x9a35 0xfb6 0x4a4a 0x99e5 0xfbe 0x4c3e 0x9991 0xfa0 0x4e32 0x9937 0xf8f 0x5027 0x98d1 0xf62 0x521c 0x986e 0xf3c 0x5411 0x9807 0xf14 0x5606 0x97a4 0xee5 0x57fb 0x9744 0xec7 0x59f0 0x96ea 0xeb8 0x5be5 0x9696 0xea6 0x5dda 0x964c 0xeb0 0x5fcf 0x9602 0xeb0 0x61c4 0x95c4 0xebf 0x63b9 0x9589 0xec6 0x65ae 0x9551 0xed6 0x67a3 0x951c 0xee5 0x6998 0x94e8 0xeef 0x6b8d 0x94b9 0xf05 0x6d82 0x948e 0xf23 0x6f77 0x9465 0xf3a 0x716b 0x9440 0xf62 0x7360 0x941e 0xf78 0x7555 0x93ff 0xf99 0x774a 0x93e6 0xf9d 0x793f 0x93d4 0xfc8 0x7b34 0x93be 0xfdf 0x7d28 0x93ab 0x1004 0x7f1c 0x9396 0x101d 0x8111 0x9383 0x1043 0x8306 0x9370 0x1061 0x84fb 0x935e 0x1081 0x86f0 0x934b 0x10ae 0x88e5 0x9332 0x10cc 0x8ada 0x931a 0x1106 0x8ccf 0x9304 0x112b 0x8ec3 0x92e8 0x1151 0x90b7 0x92cc 0x1179 0x92ab 0x92a7 0x1197 0x94a0 0x927f 0x11ce 0x9695 0x9253 0x11ec 0x988a 0x9222 0x120c 0x9a7f 0x91ed 0x122a 0x9c73 0x91b5 0x1252 0x9e67 0x9171 0x1270 0xa05b 0x9123 0x1296 0xa24f 0x90d0 0x12b6 0xa443 0x9076 0x12e6 0xa637 0x900f 0x1301 0xa82b 0x8fa0 0x1313 0xaa20 0x8f27 0x133a 0xac15 0x8ea8 0x1359 0xae0a 0x8e1c 0x1377 0xafff 0x8d8e 0x1397 0xb1f4 0x8cf9 0x13ae 0xb3e9 0x8c71 0x13f6 0xb5de 0x8beb 0x1450 0xb7d3 0x8b69 0x14e4 0xb9c8 0x8aea 0x15c4 0xbbbd 0x8a5b 0x16ec 0xbdb2 0x89b1 0x18b5 0xbfa7 0x8890 0x1b26 0xc19c 0x869a 0x1f6d>;
		battery0_profile_t0_num = <0x64>;
		g_FG_PSEUDO100_T4 = <0x5f>;
		Q_MAX_SYS_VOLTAGE_BAT3 = <0xd16>;
		battery0_profile_t4 = <0x00 0xab90 0x23f0 0x203 0xaa42 0x241e 0x405 0xa91f 0x277a 0x608 0xa81d 0x26e1 0x80b 0xa73a 0x2620 0xa0e 0xa667 0x2558 0xc10 0xa59e 0x24b3 0xe13 0xa4ec 0x2415 0x1016 0xa43d 0x2384 0x1219 0xa395 0x230a 0x141b 0xa2f2 0x229b 0x161e 0xa25a 0x2232 0x1821 0xa1c1 0x21cf 0x1a24 0xa131 0x2185 0x1c26 0xa0af 0x214d 0x1e29 0xa031 0x2127 0x202c 0x9fc3 0x2140 0x222f 0x9f63 0x1cc1 0x2431 0x9eb2 0x1ff3 0x2634 0x9e08 0x200b 0x2837 0x9d56 0x1f8f 0x2a3a 0x9cba 0x1f26 0x2c3c 0x9c28 0x1ec2 0x2e3f 0x9ba2 0x1e8c 0x3042 0x9b31 0x1e54 0x3245 0x9ac8 0x1e37 0x3447 0x9a62 0x1e28 0x364a 0x9a03 0x1e24 0x384d 0x99a5 0x1e16 0x3a50 0x994b 0x1e05 0x3c52 0x98f2 0x1df6 0x3e55 0x9893 0x1de6 0x4058 0x9835 0x1dd0 0x425b 0x97dd 0x1dbd 0x445d 0x9781 0x1dac 0x4660 0x972b 0x1dae 0x4863 0x96d7 0x1db0 0x4a66 0x9683 0x1dc1 0x4c68 0x9638 0x1dc4 0x4e6b 0x95e4 0x1dba 0x506e 0x95a5 0x1dba 0x5271 0x955c 0x1dd0 0x5473 0x9527 0x1df0 0x5676 0x94e9 0x1e13 0x5879 0x94b5 0x1e45 0x5a7c 0x9480 0x1e6f 0x5c7e 0x944f 0x1e9f 0x5e81 0x9425 0x1edb 0x6084 0x93fb 0x1f13 0x6287 0x93cc 0x1f4e 0x6489 0x939d 0x1f92 0x668c 0x9373 0x1fd5 0x688f 0x9343 0x2009 0x6a92 0x9315 0x2045 0x6c94 0x92e4 0x207c 0x6e97 0x92b7 0x20b9 0x709a 0x9285 0x20f8 0x729d 0x9250 0x2140 0x749f 0x921c 0x2189 0x76a2 0x91dd 0x21b5 0x78a5 0x91b2 0x21fe 0x7aa8 0x9174 0x223c 0x7caa 0x913e 0x2272 0x7ead 0x9101 0x22b5 0x80b0 0x90ca 0x2304 0x82b3 0x908b 0x2343 0x84b5 0x904c 0x237f 0x86b8 0x900d 0x23bb 0x88bb 0x8fce 0x2404 0x8abe 0x8f8f 0x2449 0x8cc0 0x8f50 0x2498 0x8ec3 0x8f11 0x24f1 0x90c6 0x8ed2 0x254b 0x92c9 0x8e93 0x25aa 0x94cb 0x8e54 0x25fa 0x96ce 0x8e15 0x265b 0x98d1 0x8dd6 0x26d5 0x9ad4 0x8d97 0x2741 0x9cd6 0x8d74 0x27f5 0x9ed9 0x8d37 0x261b 0xa0dc 0x8cee 0x2901 0xa2df 0x8caf 0x29ba 0xa4e1 0x8c70 0x2a51 0xa6e4 0x8c30 0x2b3e 0xa8e7 0x8bf1 0x2c1d 0xaaea 0x8bb5 0x2d13 0xacec 0x8b7a 0x2e24 0xaeef 0x8b34 0x2f2c 0xb0f2 0x8af1 0x305e 0xb2f5 0x8aa2 0x31b3 0xb4f7 0x8a4e 0x3319 0xb6fa 0x89ee 0x34a6 0xb8fd 0x897f 0x3651 0xbb00 0x88f6 0x383e 0xbd02 0x884d 0x3a80 0xbf05 0x8772 0x3d57 0xc108 0x8650 0x40ff 0xc30b 0x84c5 0x460b 0xc50d 0x849e 0x468c 0xc710 0x849e 0x468c>;
		battery0_profile_t4_num = <0x64>;
		SHUTDOWN_GAUGE0_VOLTAGE = <0x84d0>;
		EMBEDDED_SEL = <0x01>;
		battery1_profile_t1_num = <0x64>;
		battery1_profile_t1 = <0x00 0xab5b 0x4df 0x1f4 0xaad9 0x4df 0x3e8 0xaa63 0x4d8 0x5dc 0xa9ea 0x4c7 0x7d0 0xa96b 0x4bf 0x9c4 0xa8ef 0x4c9 0xbb8 0xa86d 0x4a9 0xdac 0xa7e8 0x4b2 0xfa0 0xa769 0x4ab 0x1194 0xa6ea 0x4a4 0x1388 0xa66a 0x483 0x157c 0xa5ee 0x483 0x1770 0xa56f 0x46a 0x1964 0xa4f3 0x472 0x1b58 0xa477 0x492 0x1d4c 0xa401 0x492 0x1f40 0xa389 0x483 0x2134 0xa313 0x47b 0x2328 0xa29a 0x48b 0x251c 0xa227 0x492 0x2710 0xa1b1 0x49a 0x2904 0xa13f 0x4ab 0x2af8 0xa0cc 0x4b2 0x2cec 0xa059 0x4b0 0x2ee0 0x9fe7 0x4ab 0x30d4 0x9f7a 0x4b3 0x32c8 0x9f11 0x4b3 0x34bc 0x9eba 0x4f1 0x36b0 0x9e69 0x517 0x38a4 0x9ded 0x4e7 0x3a98 0x9d5f 0x4e2 0x3c8c 0x9cd3 0x4df 0x3e80 0x9c60 0x4ef 0x4074 0x9c03 0x50d 0x4268 0x9bbf 0x534 0x445c 0x9b81 0x544 0x4650 0x9b34 0x537 0x4844 0x9ae0 0x544 0x4a38 0x9a89 0x564 0x4c2c 0x9a35 0x582 0x4e20 0x99e2 0x594 0x5014 0x9988 0x59b 0x5208 0x9928 0x59b 0x53fc 0x98af 0x55c 0x55f0 0x9826 0x505 0x57e4 0x97a4 0x4b8 0x59d8 0x973b 0x483 0x5bcc 0x96e7 0x483 0x5dc0 0x969d 0x47b 0x5fb4 0x965c 0x483 0x61a8 0x9621 0x48b 0x639c 0x95e6 0x47c 0x6590 0x95ae 0x465 0x6784 0x957f 0x472 0x6978 0x954b 0x474 0x6b6c 0x9522 0x481 0x6d60 0x94fa 0x48b 0x6f54 0x94cf 0x48b 0x7148 0x94a3 0x48b 0x733c 0x9481 0x492 0x7530 0x945c 0x492 0x7724 0x943d 0x4a9 0x7918 0x941b 0x4a1 0x7b0c 0x9402 0x4b0 0x7d00 0x93e9 0x4c9 0x7ef4 0x93d1 0x4d0 0x80e8 0x93bb 0x4d1 0x82dc 0x93a8 0x4d1 0x84d0 0x939c 0x4f9 0x86c4 0x938c 0x505 0x88b8 0x9380 0x50f 0x8aac 0x9377 0x517 0x8ca0 0x9367 0x517 0x8e94 0x9351 0x50d 0x9088 0x9332 0x4f6 0x927c 0x9313 0x4ef 0x9470 0x92f4 0x4ef 0x9664 0x92d2 0x4e7 0x9858 0x92b0 0x4fe 0x9a4c 0x9288 0x500 0x9c40 0x9269 0x517 0x9e34 0x924a 0x51e 0xa028 0x9225 0x526 0xa21c 0x91f9 0x51e 0xa410 0x91c8 0x52d 0xa604 0x9187 0x537 0xa7f8 0x9145 0x535 0xa9ec 0x910b 0x53f 0xabe0 0x90c9 0x553 0xadd4 0x9066 0x57b 0xafc8 0x9013 0x5a3 0xb1bc 0x8fde 0x5e1 0xb3b0 0x8f87 0x5ff 0xb5a4 0x8eef 0x607 0xb798 0x8deb 0x5e1 0xb98c 0x8cbb 0x5c0 0xbb80 0x8b9b 0x5c1 0xbd74 0x8a5b 0x5b9 0xbf68 0x885c 0x5b2 0xc15c 0x85ca 0x5f5>;
		g_FG_PSEUDO100_T2 = <0x5f>;
		battery1_profile_t5_num = <0x64>;
		Q_MAX_SYS_VOLTAGE_BAT1 = <0xd16>;
		KEEP_100_PERCENT = <0x01>;
		battery0_profile_t2 = <0x00 0xab7c 0x83e 0x203 0xaade 0x84c 0x405 0xaa44 0x956 0x608 0xa9c1 0x94d 0x80b 0xa928 0x91a 0xa0e 0xa8a2 0x912 0xc10 0xa824 0x8fc 0xe13 0xa7a2 0x8ee 0x1016 0xa722 0x8c8 0x1219 0xa6a9 0x8c4 0x141b 0xa626 0x8b6 0x161e 0xa5a3 0x887 0x1821 0xa52b 0x87a 0x1a24 0xa4b8 0x87a 0x1c26 0xa436 0x865 0x1e29 0xa3bd 0x85c 0x202c 0xa351 0x85c 0x222f 0xa2e0 0x85c 0x2431 0xa26c 0x877 0x2634 0xa202 0x87a 0x2837 0xa17b 0x821 0x2a3a 0xa107 0x85c 0x2c3c 0xa095 0x85f 0x2e3f 0xa02a 0x87a 0x3042 0x9fb9 0x880 0x3245 0x9f50 0x890 0x3447 0x9ef0 0x88d 0x364a 0x9e9f 0x8b6 0x384d 0x9e38 0x8b6 0x3a50 0x9db2 0x8a8 0x3c52 0x9d15 0x898 0x3e55 0x9c6c 0x887 0x4058 0x9bd2 0x87a 0x425b 0x9b50 0x866 0x445d 0x9ae7 0x872 0x4660 0x9a98 0x891 0x4863 0x9a47 0x87f 0x4a66 0x99f3 0x846 0x4c68 0x999e 0x83e 0x4e6b 0x9954 0x85b 0x506e 0x98e2 0x81f 0x5271 0x987a 0x7db 0x5473 0x981b 0x7e0 0x5676 0x97bb 0x7bf 0x5879 0x9758 0x797 0x5a7c 0x970f 0x778 0x5c7e 0x96c5 0x779 0x5e81 0x967c 0x7a4 0x6084 0x9632 0x785 0x6287 0x95e9 0x762 0x6489 0x95aa 0x762 0x668c 0x9575 0x78a 0x688f 0x9541 0x7a2 0x6a92 0x950c 0x79e 0x6c94 0x94df 0x788 0x6e97 0x94ad 0x780 0x709a 0x9481 0x780 0x729d 0x9460 0x79a 0x749f 0x942e 0x782 0x76a2 0x940d 0x79d 0x78a5 0x93ed 0x7bb 0x7aa8 0x93c4 0x79e 0x7caa 0x93a4 0x79e 0x7ead 0x9386 0x7a0 0x80b0 0x9374 0x7ad 0x82b3 0x9366 0x7c7 0x84b5 0x9351 0x7da 0x86b8 0x9344 0x7d2 0x88bb 0x9337 0x7e4 0x8abe 0x9321 0x7f3 0x8cc0 0x9317 0x802 0x8ec3 0x9300 0x814 0x90c6 0x92e7 0x833 0x92c9 0x92d9 0x853 0x94cb 0x92c0 0x872 0x96ce 0x92a8 0x892 0x98d1 0x9282 0x87f 0x9ad4 0x9250 0x87a 0x9cd6 0x9237 0x8b2 0x9ed9 0x9205 0x8b6 0xa0dc 0x91da 0x8f4 0xa2df 0x91af 0x91d 0xa4e1 0x916e 0x930 0xa6e4 0x9121 0x908 0xa8e7 0x90c9 0x94e 0xaaea 0x9082 0x992 0xacec 0x9023 0x99c 0xaeef 0x8fb9 0x9bc 0xb0f2 0x8f36 0x9ce 0xb2f5 0x8eb3 0x9dd 0xb4f7 0x8e35 0x9ec 0xb6fa 0x8db1 0xa22 0xb8fd 0x8d15 0xa39 0xbb00 0x8c6c 0xa16 0xbd02 0x8bae 0xa3e 0xbf05 0x8ace 0xa68 0xc108 0x89bd 0xaa1 0xc30b 0x8808 0xaaa 0xc50d 0x858f 0xae3 0xc710 0x8278 0xbfe>;
		battery0_profile_t2_col = <0x03>;
	};

    i2c2@11009000 {
		clock-div = <0x05>;
		rsel_cfg = <0xf0>;
		eh_cfg = <0x40>;
		#address-cells = <0x01>;
		scl-gpio-id = <0x67>;
		sda-gpio-id = <0x68>;
		clock-names = "main\0dma";
		ch_offset_ccu = <0x200>;
		ch_offset_default = <0x100>;
		id = <0x02>;
		interrupts = <0x00 0x6b 0x08>;
		clocks = <0x26 0x0b 0x26 0x26>;
		#size-cells = <0x00>;
		clock-frequency = <0x61a80>;
		compatible = "mediatek,i2c";
		reg = <0x00 0x11009000 0x00 0x1000 0x00 0x11000180 0x00 0x180>;
		mem_len = <0x200>;
		aed = <0x1a>;
		mediatek,use-open-drain;
		phandle = <0xc4>;
		gpio_start = <0x10002800>;
		pu_cfg = <0xa0>;

		ccu_sensor_i2c_2_hw@11 {
			compatible = "mediatek,ccu_sensor_i2c_2_hw";
			status = "okay";
			reg = <0x11>;
			phandle = <0x158>;
		};

		camera_main@1a {
			compatible = "mediatek,camera_main";
			status = "okay";
			reg = <0x1a>;
			phandle = <0x155>;
		};

		camera_main_eeprom@50 {
			compatible = "mediatek,camera_main_eeprom";
			status = "okay";
			reg = <0x50>;
			phandle = <0x156>;
		};

		mtk-usb@60 {
			compatible = "mediatek,mtk-usb";
			status = "okay";
			reg = <0x60>;
		};

		camera_main_af@0c {
			compatible = "mediatek,camera_main_af";
			status = "okay";
			reg = <0x0c>;
			phandle = <0x157>;
		};
	};

    kp@10010000 {
		pinctrl-names = "default";
		mediatek,kpd-hw-dl-key1 = <0x00>;
		mediatek,kpd-use-extend-type = <0x00>;
		pinctrl-0 = <0x110>;
		clock-names = "kpd";
		interrupts = <0x00 0x49 0x02>;
		clocks = <0x15>;
		mediatek,kpd-key-debounce = <0x400>;
		mediatek,kpd-pwkey-gpio-din = <0x00>;
		mediatek,kpd-sw-rstkey = <0x73>;
		mediatek,kpd-sw-pwrkey = <0x74>;
		compatible = "mediatek,kp";
		mediatek,kpd-hw-dl-key2 = <0x08>;
		mediatek,kpd-hw-factory-key = <0x00>;
		status = "okay";
		mediatek,kpd-hw-map-num = <0x48>;
		mediatek,boot_mode = <0x01>;
		mediatek,kpd-hw-dl-key0 = <0x11>;
		reg = <0x00 0x10010000 0x00 0x1000>;
		phandle = <0xac>;
		mediatek,kpd-hw-init-map = <0x72 0x00 0x00 0x00 0x00 0x00 0x00 0x00 0x00 0x00 0x00 0x00 0x00 0x00 0x00 0x00 0x00 0x00 0x00 0x00 0x00 0x00 0x00 0x00 0x00 0x00 0x00 0x00 0x00 0x00 0x00 0x00 0x00 0x00 0x00 0x00 0x00 0x00 0x00 0x00 0x00 0x00 0x00 0x00 0x00 0x00 0x00 0x00 0x00 0x00 0x00 0x00 0x00 0x00 0x00 0x00 0x00 0x00 0x00 0x00 0x00 0x00 0x00 0x00 0x00 0x00 0x00 0x00 0x00 0x00 0x00 0x00>;
		mediatek,kpd-hw-rstkey = <0x11>;
		mediatek,kpd-hw-pwrkey = <0x08>;
		mediatek,kpd-pwrkey-eint-gpio = <0x00>;
		mediatek,kpd-hw-recovery-key = <0x11>;
	};

	snd_scp_ultra {
		scp_ultra_ul_memif_id = <0x05>;
		compatible = "mediatek,snd_scp_ultra";
		phandle = <0xde>;
		scp_ultra_dl_memif_id = <0x03>;
	};

	mdp_rdma0@14004000 {
		clock-names = "MDP_RDMA0";
		interrupts = <0x00 0xe0 0x08>;
		clocks = <0x2b 0x00>;
		compatible = "mediatek,mdp_rdma0";
		reg = <0x00 0x14004000 0x00 0x1000>;
		phandle = <0x2c>;
	};

	cldmadriver@10014000 {
		mediatek,cldma_capability = <0x06>;
		clock-names = "infra-cldma-bclk";
		interrupts = <0x00 0xb4 0x04>;
		clocks = <0x26 0x32>;
		compatible = "mediatek,ccci_cldma";
		cldma-infracfg = <0x26>;
		reg = <0x00 0x10014000 0x00 0x1000 0x00 0x1021b000 0x00 0x1000>;
		phandle = <0xb4>;
		mediatek,md_generation = <0x1895>;
		mediatek,platform = <0x1a53>;
	};

	vdec_mbist_ctrl@16001000 {
		compatible = "mediatek,vdec_mbist_ctrl";
		reg = <0x00 0x16001000 0x00 0x1000>;
	};

    pinctrl {
		gpio-controller;
		interrupts = <0x00 0xba 0x04>;
		pins-are-numbered;
		compatible = "mediatek,mt6768-pinctrl";
		#interrupt-cells = <0x04>;
		reg_base_eint = <0x1f>;
		phandle = <0x20>;
		reg_bases = <0x16 0x17 0x18 0x19 0x1a 0x1b 0x1c 0x1d 0x1e>;
		#gpio-cells = <0x02>;
		gpio-ranges = <0x20 0x00 0x00 0xba>;
		interrupt-controller;

		ocp81375hwen_high {
			phandle = <0x12c>;

			pins_cmd_dat {
				output-high;
				pinmux = <0x9600>;
				slew-rate = <0x01>;
			};
		};

		gpio_eint_pull_down {
			phandle = <0x10c>;

			pins_cmd_dat {
				pinmux = <0x800>;
				bias-pull-down = <0x00>;
				slew-rate = <0x00>;
				output-low;
			};
		};

		lcd_disp_pwm0_gpio {
			phandle = <0x11f>;

			pins_cmd_dat {
				pinmux = <0x2b00>;
				slew-rate = <0x01>;
				output-low;
			};
		};

		aud_clk_mosi_on {
			phandle = <0x49>;

			pins_cmd1_dat {
				pinmux = <0x8901>;
				input-schmitt-enable;
			};

			pins_cmd0_dat {
				pinmux = <0x8801>;
				input-schmitt-enable;
			};
		};

		eintoutput1 {
			phandle = <0x127>;

			pins_cmd_dat {
				output-high;
				pinmux = <0x100>;
				slew-rate = <0x01>;
			};
		};

		camera0_mclk_gpio_mode@gpio99 {
			phandle = <0x139>;

			pins_cmd_dat {
				drive-strength = <0x04>;
				pinmux = <0x6300>;
			};
		};

		6382_rst_out0_gpio {
			phandle = <0x121>;

			pins_cmd_dat {
				pinmux = <0x1300>;
				slew-rate = <0x01>;
				output-low;
			};
		};

		irtx_gpio_led_set@gpio12 {
			phandle = <0x116>;

			pins_cmd_dat {
				output-high;
				pinmux = <0xc01>;
				slew-rate = <0x01>;
			};
		};

		mmc0default {
			phandle = <0x3a>;

			pins_rst {
				drive-strength = <0x04>;
				pinmux = <0x8501>;
				bias-pull-up = <0x65>;
			};

			pins_clk {
				drive-strength = <0x04>;
				pinmux = <0x7c01>;
				bias-pull-down = <0x66>;
			};

			pins_cmd_dat {
				drive-strength = <0x04>;
				pinmux = <0x7b01 0x8001 0x7d01 0x8401 0x7e01 0x8101 0x7f01 0x8201 0x7a01>;
				bias-pull-up = <0x65>;
				input-enable;
			};

			pins_ds {
				drive-strength = <0x04>;
				pinmux = <0x8301>;
				bias-pull-down = <0x66>;
			};
		};

		camdefault {
			phandle = <0x12e>;
		};

		camera2_rst_output_high@gpio109 {
			phandle = <0x134>;

			pins_cmd_dat {
				output-high;
				pinmux = <0x6d00>;
			};
		};

		mmc0@1 {
			phandle = <0x3c>;

			pins_rst {
				drive-strength = <0x04>;
				pinmux = <0x8501>;
				bias-pull-up = <0x65>;
			};

			pins_clk {
				drive-strength = <0x04>;
				pinmux = <0x7c01>;
				bias-pull-down = <0x66>;
			};

			pins_cmd_dat {
				drive-strength = <0x04>;
				pinmux = <0x7b01 0x8001 0x7d01 0x8401 0x7e01 0x8101 0x7f01 0x8201 0x7a01>;
				bias-pull-down = <0x66>;
				input-enable;
			};

			pins_ds {
				drive-strength = <0x04>;
				pinmux = <0x8301>;
				bias-pull-down = <0x66>;
			};
		};

		rstoutput1 {
			phandle = <0x129>;

			pins_cmd_dat {
				output-high;
				pinmux = <0x2400>;
				slew-rate = <0x01>;
			};
		};

		mmc1default {
			phandle = <0x3e>;

			pins_clk {
				drive-strength = <0x03>;
				pinmux = <0xab01>;
				bias-pull-down = <0x66>;
			};

			pins_cmd_dat {
				drive-strength = <0x03>;
				pinmux = <0xa401 0xa301 0xa201 0xa101 0xaa01>;
				bias-pull-up = <0x65>;
				input-enable;
			};

			pins_insert {
				pinmux = <0x1200>;
				bias-pull-up;
			};
		};

		aud_gpio_i2s2_off {
			phandle = <0x54>;
		};

		camera2_mclk_8mA@gpio111 {
			phandle = <0x147>;

			pins_cmd_dat {
				drive-strength = <0x07>;
				pinmux = <0x6f01>;
			};
		};

		lcd_bias_enn1_gpio {
			phandle = <0x11b>;

			pins_cmd_dat {
				output-high;
				pinmux = <0xa500>;
				slew-rate = <0x01>;
			};
		};

		eint0default {
			phandle = <0x124>;
		};

		camera0_mclk_8mA@gpio99 {
			phandle = <0x13d>;

			pins_cmd_dat {
				drive-strength = <0x07>;
				pinmux = <0x6301>;
			};
		};

		camera1_mclk_8mA@gpio100 {
			phandle = <0x142>;

			pins_cmd_dat {
				drive-strength = <0x07>;
				pinmux = <0x6401>;
			};
		};

		aud_gpio_i2s3_on {
			phandle = <0x57>;

			pins_cmd_dat {
				pinmux = <0x2502 0x2602 0x2402>;
			};
		};

		aud_gpio_i2s0_on {
			phandle = <0x51>;

			pins_cmd_dat {
				pinmux = <0x2802>;
			};
		};

		aud_pins_extamp_low {
			phandle = <0x123>;

			pins_cmd_dat {
				pinmux = <0x9e00>;
				slew-rate = <0x01>;
				output-low;
			};
		};

		camera2_mclk_gpio_mode@gpio111 {
			phandle = <0x143>;

			pins_cmd_dat {
				drive-strength = <0x04>;
				pinmux = <0x6f00>;
			};
		};

		lcd_bias_enn0_gpio {
			phandle = <0x11c>;

			pins_cmd_dat {
				pinmux = <0xa500>;
				slew-rate = <0x01>;
				output-low;
			};
		};

		camera0_mclk_4mA@gpio99 {
			phandle = <0x13b>;

			pins_cmd_dat {
				drive-strength = <0x04>;
				pinmux = <0x6301>;
			};
		};

		camera2_mclk_6mA@gpio111 {
			phandle = <0x146>;

			pins_cmd_dat {
				drive-strength = <0x06>;
				pinmux = <0x6f01>;
			};
		};

		rst_out_zero {
			phandle = <0x10e>;

			pins_cmd_dat {
				bias-disable;
				pinmux = <0x1400>;
				slew-rate = <0x01>;
				output-low;
			};
		};

		lcm_rst_out1_gpio {
			phandle = <0x117>;

			pins_cmd_dat {
				output-high;
				pinmux = <0x2d00>;
				slew-rate = <0x01>;
			};
		};

		camera2_rst_output_low@gpio109 {
			phandle = <0x133>;

			pins_cmd_dat {
				pinmux = <0x6d00>;
				output-low;
			};
		};

		mmc1@0 {
			phandle = <0x3f>;

			pins_clk {
				drive-strength = <0x03>;
				pinmux = <0xab01>;
			};

			pins_cmd_dat {
				drive-strength = <0x03>;
				pinmux = <0xa401 0xa301 0xa201 0xa101 0xaa01>;
				input-enable;
			};
		};

		gpslna@2 {
			phandle = <0x114>;

			pins_cmd_dat {
				pinmux = <0x5e00>;
				slew-rate = <0x01>;
				output-low;
			};
		};

		aud_gpio_i2s3_off {
			phandle = <0x56>;

			pins_cmd_dat {
				pinmux = <0x2500 0x2600 0x2400>;
			};
		};

		camera1_mclk_6mA@gpio100 {
			phandle = <0x141>;

			pins_cmd_dat {
				drive-strength = <0x06>;
				pinmux = <0x6401>;
			};
		};

		fingerprint_default {
			phandle = <0x10a>;
		};

		camera1_mclk_gpio_mode@gpio100 {
			phandle = <0x13e>;

			pins_cmd_dat {
				drive-strength = <0x04>;
				pinmux = <0x6400>;
			};
		};

		ocp81375default {
			phandle = <0x12b>;
		};

		consys_default {
			phandle = <0x111>;
		};

		gpslna@0 {
			phandle = <0x112>;

			pins_cmd_dat {
				bias-disable;
				pinmux = <0x5e00>;
				slew-rate = <0x00>;
				output-low;
			};
		};

		camera2_pdn_output_low@gpio110 {
			phandle = <0x135>;

			pins_cmd_dat {
				pinmux = <0x6e00>;
				output-low;
			};
		};

		camera1_rst_output_high@gpio102 {
			phandle = <0x132>;

			pins_cmd_dat {
				output-high;
				pinmux = <0x6600>;
			};
		};

		lcm_rst_out0_gpio {
			phandle = <0x118>;

			pins_cmd_dat {
				pinmux = <0x2d00>;
				slew-rate = <0x01>;
				output-low;
			};
		};

		camera2_mclk_4mA@gpio111 {
			phandle = <0x145>;

			pins_cmd_dat {
				drive-strength = <0x04>;
				pinmux = <0x6f01>;
			};
		};

		aud_dat_miso_on {
			phandle = <0x4f>;

			pins_cmd1_dat {
				pinmux = <0x8d01>;
				input-schmitt-enable;
			};

			pins_cmd2_dat {
				pinmux = <0x8e01>;
				input-schmitt-enable;
			};

			pins_cmd3_dat {
				pinmux = <0x8f01>;
				input-schmitt-enable;
			};

			pins_cmd0_dat {
				pinmux = <0x8c01>;
				input-schmitt-enable;
			};
		};

		vow_dat_miso_off {
			phandle = <0x58>;

			pins_cmd1_dat {
				pinmux = <0x8e00>;
			};
		};

		aud_pins_extamp_high {
			phandle = <0x122>;

			pins_cmd_dat {
				output-high;
				pinmux = <0x9e00>;
				slew-rate = <0x01>;
			};
		};

		spimode_default {
			phandle = <0x12a>;

			pins_cmd_dat {
				drive-strength = <0x04>;
				pinmux = <0x1c02 0x1902 0x1a02 0x1b02>;
			};
		};

		eintoutput0 {
			phandle = <0x126>;

			pins_cmd_dat {
				pinmux = <0x100>;
				slew-rate = <0x01>;
				output-low;
			};
		};

		aud_gpio_i2s2_on {
			phandle = <0x55>;
		};

		camera0_rst_output_high@gpio101 {
			phandle = <0x130>;

			pins_cmd_dat {
				output-high;
				pinmux = <0x6500>;
			};
		};

		camera0_vcamd_output_low@gpio179 {
			phandle = <0x138>;

			pins_cmd_dat {
				pinmux = <0xb300>;
				output-low;
			};
		};

		aud_gpio_i2s0_off {
			phandle = <0x50>;

			pins_cmd_dat {
				pinmux = <0x2800>;
			};
		};

		vow_dat_miso_on {
			phandle = <0x59>;

			pins_cmd1_dat {
				pinmux = <0x8e04>;
			};
		};

		camera1_mclk_4mA@gpio100 {
			phandle = <0x140>;

			pins_cmd_dat {
				drive-strength = <0x04>;
				pinmux = <0x6401>;
			};
		};

		gpio_eint {
			phandle = <0x10b>;

			pins_cmd_dat {
				bias-disable;
				pinmux = <0x800>;
				slew-rate = <0x00>;
			};
		};

		aud_dat_mosi_on {
			phandle = <0x4d>;

			pins_cmd1_dat {
				pinmux = <0x8901>;
				input-schmitt-enable;
			};

			pins_cmd2_dat {
				pinmux = <0x8a01>;
				input-schmitt-enable;
			};

			pins_cmd3_dat {
				pinmux = <0x8b01>;
				input-schmitt-enable;
			};

			pins_cmd0_dat {
				pinmux = <0x8801>;
				input-schmitt-enable;
			};
		};

		lcd_bias_enp1_gpio {
			phandle = <0x119>;

			pins_cmd_dat {
				output-high;
				pinmux = <0xa900>;
				slew-rate = <0x01>;
			};
		};

		mmc0@0 {
			phandle = <0x3b>;

			pins_rst {
				drive-strength = <0x04>;
				pinmux = <0x8501>;
			};

			pins_clk {
				drive-strength = <0x04>;
				pinmux = <0x7c01>;
			};

			pins_cmd_dat {
				drive-strength = <0x04>;
				pinmux = <0x7b01 0x8001 0x7d01 0x8401 0x7e01 0x8101 0x7f01 0x8201 0x7a01>;
				input-enable;
			};

			pins_ds {
				drive-strength = <0x04>;
				pinmux = <0x8301>;
			};
		};

		eint@0 {
			phandle = <0x125>;

			pins_cmd_dat {
				bias-disable;
				pinmux = <0x100>;
				slew-rate = <0x00>;
			};
		};

		camera2_pdn_output_high@gpio110 {
			phandle = <0x136>;

			pins_cmd_dat {
				output-high;
				pinmux = <0x6e00>;
			};
		};

		rstoutput0 {
			phandle = <0x128>;

			pins_cmd_dat {
				pinmux = <0x2400>;
				slew-rate = <0x01>;
				output-low;
			};
		};

		irtx_gpio_led_def@gpio12 {
			phandle = <0x115>;

			pins_cmd_dat {
				bias-disable;
				pinmux = <0xc00>;
				input-schmitt-enable = <0x00>;
				slew-rate = <0x01>;
				output-low;
			};
		};

		vow_clk_miso_off {
			phandle = <0x5a>;

			pins_cmd3_dat {
				pinmux = <0x8f00>;
			};
		};

		aud_dat_miso_off {
			phandle = <0x4e>;

			pins_cmd1_dat {
				bias-disable;
				pinmux = <0x8d00>;
				slew-rate = <0x00>;
				input-enable;
			};

			pins_cmd2_dat {
				bias-disable;
				pinmux = <0x8e00>;
				slew-rate = <0x00>;
				input-enable;
			};

			pins_cmd3_dat {
				bias-disable;
				pinmux = <0x8f00>;
				slew-rate = <0x00>;
				input-enable;
			};

			pins_cmd0_dat {
				bias-disable;
				pinmux = <0x8c00>;
				slew-rate = <0x00>;
				input-enable;
			};
		};

		rst_out_one {
			phandle = <0x10d>;

			pins_cmd_dat {
				bias-disable;
				output-high;
				pinmux = <0x1400>;
				slew-rate = <0x01>;
			};
		};

		camera2_mclk_2mA@gpio111 {
			phandle = <0x144>;

			pins_cmd_dat {
				drive-strength = <0x02>;
				pinmux = <0x6f01>;
			};
		};

		kpdgpiodefault {
			phandle = <0x110>;

			pins_cmd_dat {
				pinmux = <0x5d01>;
				input-schmitt-enable;
				bias-pull-up = <0x66>;
				input-enable;
			};
		};

		camera0_mclk_6mA@gpio99 {
			phandle = <0x13c>;

			pins_cmd_dat {
				drive-strength = <0x06>;
				pinmux = <0x6301>;
			};
		};

		camera1_rst_output_low@gpio102 {
			phandle = <0x131>;

			pins_cmd_dat {
				pinmux = <0x6600>;
				output-low;
			};
		};

		lcm_dsi_te {
			phandle = <0x11d>;

			pins_cmd_dat {
				pinmux = <0x2c01>;
			};
		};

		lcd_bias_enp0_gpio {
			phandle = <0x11a>;

			pins_cmd_dat {
				pinmux = <0xa900>;
				slew-rate = <0x01>;
				output-low;
			};
		};

		mmc1@1 {
			phandle = <0x40>;

			pins_clk {
				drive-strength = <0x03>;
				pinmux = <0xab01>;
				bias-pull-down = <0x66>;
			};

			pins_cmd_dat {
				drive-strength = <0x03>;
				pinmux = <0xa401 0xa301 0xa201 0xa101 0xaa01>;
				bias-pull-down = <0x66>;
				input-enable;
			};
		};

		aud_dat_mosi_off {
			phandle = <0x4c>;

			pins_cmd1_dat {
				bias-disable;
				pinmux = <0x8900>;
				slew-rate = <0x00>;
				input-enable;
			};

			pins_cmd2_dat {
				bias-disable;
				pinmux = <0x8a00>;
				slew-rate = <0x00>;
				input-enable;
			};

			pins_cmd3_dat {
				pinmux = <0x8b00>;
				bias-pull-down;
				slew-rate = <0x00>;
				input-enable;
			};

			pins_cmd0_dat {
				bias-disable;
				pinmux = <0x8800>;
				slew-rate = <0x00>;
				input-enable;
			};
		};

		camera1_mclk_2mA@gpio100 {
			phandle = <0x13f>;

			pins_cmd_dat {
				drive-strength = <0x02>;
				pinmux = <0x6401>;
			};
		};

		camera0_vcamd_output_high@gpio179 {
			phandle = <0x137>;

			pins_cmd_dat {
				output-high;
				pinmux = <0xb300>;
			};
		};

		aud_clk_miso_off {
			phandle = <0x4a>;

			pins_cmd0_dat {
				pinmux = <0x8c00 0x8d00>;
			};
		};

		lcd_disp_pwm1_gpio {
			phandle = <0x11e>;

			pins_cmd_dat {
				output-high;
				pinmux = <0x2b00>;
				slew-rate = <0x01>;
			};
		};

		aud_gpio_i2s1_off {
			phandle = <0x52>;
		};

		spislv_mode_default {
			phandle = <0x10f>;

			pins_cmd_dat {
				drive-strength = <0x03>;
				pinmux = <0xd02 0xf02 0x1002 0xe02>;
			};
		};

		6382_rst_out1_gpio {
			phandle = <0x120>;

			pins_cmd_dat {
				output-high;
				pinmux = <0x1300>;
				slew-rate = <0x01>;
			};
		};

		camera0_mclk_2mA@gpio99 {
			phandle = <0x13a>;

			pins_cmd_dat {
				drive-strength = <0x02>;
				pinmux = <0x6301>;
			};
		};

		gpslna@1 {
			phandle = <0x113>;

			pins_cmd_dat {
				output-high;
				pinmux = <0x5e00>;
				slew-rate = <0x01>;
			};
		};

		camera0_rst_output_low@gpio101 {
			phandle = <0x12f>;

			pins_cmd_dat {
				pinmux = <0x6500>;
				output-low;
			};
		};

		aud_clk_miso_on {
			phandle = <0x4b>;

			pins_cmd1_dat {
				pinmux = <0x8d01>;
				input-schmitt-enable;
			};

			pins_cmd0_dat {
				pinmux = <0x8c01>;
				input-schmitt-enable;
			};
		};

		aud_gpio_i2s1_on {
			phandle = <0x53>;
		};

		ocp81375hwen_low {
			phandle = <0x12d>;

			pins_cmd_dat {
				pinmux = <0x9600>;
				slew-rate = <0x01>;
				output-low;
			};
		};

		aud_clk_mosi_off {
			phandle = <0x48>;

			pins_cmd0_dat {
				pinmux = <0x8800 0x8900>;
			};
		};

		vow_clk_miso_on {
			phandle = <0x5b>;

			pins_cmd3_dat {
				pinmux = <0x8f04>;
			};
		};
	};
};
